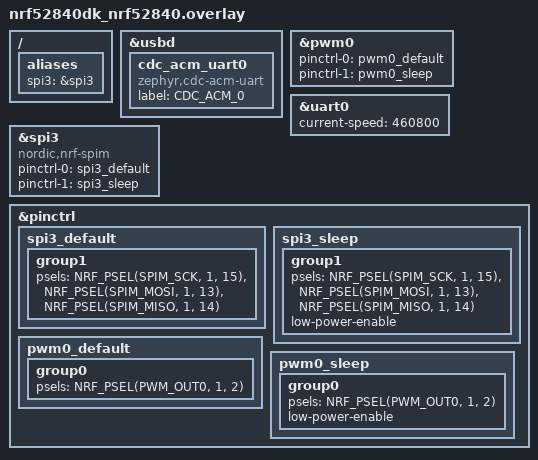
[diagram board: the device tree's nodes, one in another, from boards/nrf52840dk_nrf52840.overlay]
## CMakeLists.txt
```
cmake_minimum_required(VERSION 3.20.0)
find_package(Zephyr REQUIRED HINTS $ENV{ZEPHYR_BASE})

project(ADS1298_Test)
target_include_directories(app PRIVATE include)

target_sources(app PRIVATE
  src/main.c
  src/ads1298.c
  src/imu_task.c
  src/ble_link.c
  src/device_id.c
)
```

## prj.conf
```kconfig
#####################################
# prj.conf — EMG(ADS1298) + IMU TX
# nRF52840 DK, BLE NUS + USB CDC + RTT log
#####################################

# =============================================================
#                    ★  BLE / NUS  ★
# =============================================================
CONFIG_BT=y
CONFIG_BT_PERIPHERAL=y
CONFIG_BT_CENTRAL=n

# 安全 / 绑定（Just-Works + SMP，加密但不要求 PIN）
CONFIG_BT_SMP=y
CONFIG_BT_BONDABLE=y
CONFIG_BT_PRIVACY=y
CONFIG_SETTINGS=y
CONFIG_BT_SETTINGS=y

# NUS 服务：TX = Server
CONFIG_BT_NUS=y
CONFIG_BT_NUS_CLIENT=n

# 吞吐 & MTU & PHY（跟 Gesture_Recognition 一致）
CONFIG_BT_CTLR_PHY_2M=y
CONFIG_BT_CTLR_DATA_LENGTH_MAX=251
CONFIG_BT_L2CAP_TX_MTU=247
CONFIG_BT_BUF_ACL_TX_SIZE=251
CONFIG_BT_BUF_ACL_RX_SIZE=251
CONFIG_BT_BUF_ACL_TX_COUNT=12
CONFIG_BT_BUF_ACL_RX_COUNT=12
CONFIG_BT_L2CAP_TX_BUF_COUNT=12
CONFIG_BT_L2CAP_TX_FRAG_COUNT=3
CONFIG_BT_CONN_TX_MAX=20
CONFIG_BT_GATT_CLIENT=y
CONFIG_BT_GATT_DM=y
CONFIG_BT_BUF_CMD_TX_COUNT=4
CONFIG_BT_BUF_EVT_RX_SIZE=255
CONFIG_BT_BUF_EVT_RX_COUNT=16
CONFIG_BT_CTLR_TX_PWR_PLUS_8=y

# 建议连接参数（约 7.5–15 ms）
CONFIG_BT_PERIPHERAL_PREF_MIN_INT=6
CONFIG_BT_PERIPHERAL_PREF_MAX_INT=12
CONFIG_BT_PERIPHERAL_PREF_LATENCY=0
CONFIG_BT_PERIPHERAL_PREF_TIMEOUT=400

# 设备名在代码里动态设置（device_bt_name_get）
CONFIG_BT_DEVICE_NAME_DYNAMIC=y

# =============================================================
#                    ★  线程 / 内存  ★
# =============================================================
CONFIG_MAIN_STACK_SIZE=4096
CONFIG_SYSTEM_WORKQUEUE_STACK_SIZE=2048
CONFIG_ISR_STACK_SIZE=2048
CONFIG_HEAP_MEM_POOL_SIZE=32768

CONFIG_THREAD_NAME=y
CONFIG_INIT_STACKS=y
# CONFIG_STACK_SENTINEL=y

# =============================================================
#                    ★  日志 / Console / RTT  ★
# =============================================================
CONFIG_LOG=y
CONFIG_LOG_MODE_DEFERRED=y
CONFIG_LOG_DEFAULT_LEVEL=3

CONFIG_USE_SEGGER_RTT=y
CONFIG_LOG_BACKEND_RTT=y
CONFIG_LOG_BACKEND_UART=n

CONFIG_PRINTK=y
CONFIG_CONSOLE=y
CONFIG_UART_CONSOLE=n         # 不占用 UART0
CONFIG_RTT_CONSOLE=y          # 控制台走 RTT，不占 CDC

# =============================================================
#                    ★  USB CDC (ADS1298 数据)  ★
# =============================================================
CONFIG_USB_DEVICE_STACK=y
CONFIG_USB_CDC_ACM=y
CONFIG_USB_DEVICE_PRODUCT="ADS1298 CDC"
CONFIG_USB_DEVICE_MANUFACTURER="BioSpur"

CONFIG_SERIAL=y
CONFIG_UART_LINE_CTRL=y

# 不让 Console 占用 CDC（我们用 RTT Console）
# 上面已设 UART_CONSOLE=n，这里就不用再关 CONSOLE 了

# =============================================================
#                    ★  GPIO / SPI / PINCTRL / PWM  ★
# =============================================================
CONFIG_GPIO=y
CONFIG_GPIO_NRFX=y
CONFIG_PINCTRL=y

CONFIG_SPI=y

CONFIG_PWM=y
CONFIG_PWM_NRFX=y

# =============================================================
#                    ★  I²C (IMU: JY901B / WT901 等)  ★
# =============================================================
CONFIG_I2C=y
CONFIG_I2C_NRFX=y
CONFIG_I2C_INIT_PRIORITY=50

# =============================================================
#                    ★  UART (预留给 UWB / BMD101 等)  ★
# =============================================================
CONFIG_UART_NRFX=y
CONFIG_UART_ASYNC_API=y
CONFIG_UART_INTERRUPT_DRIVEN=y
CONFIG_RING_BUFFER=y

# =============================================================
#                    ★  ADC  ★
# =============================================================
# 不用 SAADC：EMG 走 ADS1298 SPI + BMD101 走 UART
CONFIG_ADC=n
CONFIG_ADC_NRFX_SAADC=n
CONFIG_ADC_ASYNC=n

# =============================================================
#                    ★  DK LED & Buttons  ★
# =============================================================
CONFIG_DK_LIBRARY=y

# =============================================================
#                    ★  libc / 浮点格式化  ★
# =============================================================
CONFIG_NEWLIB_LIBC=y
CONFIG_CBPRINTF_FP_SUPPORT=y

# =============================================================
#                    ★  同步 / 信号量上限  ★
# =============================================================
CONFIG_SEM_VALUE_MAX=32767

# =============================================================
#                    ★  电源管理  ★
# =============================================================
# 关闭自动省电，避免 SPI / USB 等被自动关掉
CONFIG_PM=n

# =============================================================
#                    ★  定时器 / 其它  ★
# =============================================================
CONFIG_NRFX_TIMER2=y
CONFIG_ASSERT=y
```

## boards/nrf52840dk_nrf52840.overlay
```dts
/ {
    aliases { spi3 = &spi3; };
};

/* 启用 USB 设备控制器 */
&usbd {
    status = "okay";

    /* 新建一个 CDC ACM 节点，label 一定要给，这个就是设备名 */
    cdc_acm_uart0: cdc_acm_uart0 {
        compatible = "zephyr,cdc-acm-uart";
        label = "CDC_ACM_0";
        status = "okay";
    };
};

/* ✅ 修正：pwm0 用 pinctrl 方式绑定到 P1.02（PWM0_CH0） */
&pwm0 {
    status = "okay";
    pinctrl-0 = <&pwm0_default>;
    pinctrl-1 = <&pwm0_sleep>;
    pinctrl-names = "default", "sleep";
};

/* UART0 是否开启随你，这里保留 */
&uart0 {
    current-speed = <460800>;
    status = "okay";
};

/* 你的 SPI3 + pinctrl（保持不变） */
&spi3 {
    compatible = "nordic,nrf-spim";
    status = "okay";
    pinctrl-0 = <&spi3_default>;
    pinctrl-1 = <&spi3_sleep>;
    pinctrl-names = "default", "sleep";
    /* 如需驱动自动控片选，取消下面注释，并在 C 里配置 spi_cfg.cs */
    // cs-gpios = <&gpio1 12 GPIO_ACTIVE_LOW>;
};

/* pinctrl 区域：保留你原来的 SPI3 分组，并新增 PWM0 分组 */
&pinctrl {
    /* ===== SPI3（保持不变） ===== */
    spi3_default: spi3_default {
        group1 {
            psels = <NRF_PSEL(SPIM_SCK,  1, 15)>,
                    <NRF_PSEL(SPIM_MOSI, 1, 13)>,
                    <NRF_PSEL(SPIM_MISO, 1, 14)>;
        };
    };
    spi3_sleep: spi3_sleep {
        group1 {
            psels = <NRF_PSEL(SPIM_SCK,  1, 15)>,
                    <NRF_PSEL(SPIM_MOSI, 1, 13)>,
                    <NRF_PSEL(SPIM_MISO, 1, 14)>;
            low-power-enable;
        };
    };

    /* ===== PWM0: 将 PWM0_CH0 绑定到 P1.02 ===== */
    pwm0_default: pwm0_default {
        group0 {
            psels = <NRF_PSEL(PWM_OUT0, 1, 2)>;   /* P1.02 */
        };
    };
    pwm0_sleep: pwm0_sleep {
        group0 {
            psels = <NRF_PSEL(PWM_OUT0, 1, 2)>;
            low-power-enable;
        };
    };
};
```

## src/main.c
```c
/* src/main.c */

#include <zephyr/kernel.h>
#include <zephyr/logging/log.h>
#include <zephyr/sys/byteorder.h>

#include "app_config.h"
#include "device_id.h"
#include "ble_link.h"
#include "ads1298.h"
#include "imu_task.h"

LOG_MODULE_REGISTER(main, LOG_LEVEL_INF);

/* ============ EMG -> BLE 'E' 帧打包 ============ */

/* EMG 帧序号（u16，溢出自然回绕） */
static uint16_t g_emg_seq = 0;

static uint16_t next_emg_seq(void)
{
    uint16_t v = g_emg_seq;
    g_emg_seq = (uint16_t)(v + 1);
    return v;
}

/* 缓存 EMG 样本：最多 EMG_SAMPLES_PER_FRAME 组，每组 8 通道 */
static int32_t emg_buf[EMG_SAMPLES_PER_FRAME][8];
static uint8_t emg_buf_count = 0;

/* 把 emg_buf 里当前攒的 sample_count 组打成一帧发出去 */
static void emg_flush_frame(uint8_t sample_count)
{
    if (sample_count == 0) {
        return;
    }

#if EN_BLE
    uint8_t  f[BLE_BUF_SIZE];
    uint16_t p = 0;

    /* 帧头：AA + 'E' */
    f[p++] = 0xAA;
    f[p++] = 'E';

    /* seq (u16 LE) */
    sys_put_le16(next_emg_seq(), &f[p]); p += 2;

    /* dev_id16（与 BT 名字一一对应） */
    sys_put_le16(device_id_get16(), &f[p]); p += 2;

    /* 全局时间戳：host_ms（按第 0 组 sample 的时间） */
    sys_put_le32(ble_link_now_host_ms(), &f[p]); p += 4;

    /* 采样率：与 ads1298.c 中 EMG_SAMPLE_RATE_SPS 一致 */
    sys_put_le16(EMG_SAMPLE_RATE_SPS, &f[p]); p += 2;

    /* 本帧包含的 sample 数（1~EMG_SAMPLES_PER_FRAME） */
    f[p++] = sample_count;

    /* 写入 sample_count 组，每组 8 通道 24bit (3B) */
    for (uint8_t s = 0; s < sample_count; s++) {
        for (int ch = 0; ch < 8; ch++) {
            int32_t v = emg_buf[s][ch];
            f[p++] = (uint8_t)((v >> 16) & 0xFF);
            f[p++] = (uint8_t)((v >>  8) & 0xFF);
            f[p++] = (uint8_t)( v        & 0xFF);
        }
    }

    (void)ble_link_send(f, p);
#else
    ARG_UNUSED(sample_count);
    /* 如果 EN_BLE=0，就什么都不发，只是丢掉缓存 */
#endif
}

/* ADS1298 每来一个时间点（8 路样本）就会回调一次 */
static void emg_frame_cb(const int32_t ch_code[8], const uint8_t status[3])
{
    ARG_UNUSED(status);

    /* 把当前这组 8 通道塞进缓存 */
    if (emg_buf_count < EMG_SAMPLES_PER_FRAME) {
        for (int i = 0; i < 8; i++) {
            emg_buf[emg_buf_count][i] = ch_code[i];
        }
        emg_buf_count++;
    }

    /* 攒满 EMG_SAMPLES_PER_FRAME 组，就打一帧发出去 */
    if (emg_buf_count >= EMG_SAMPLES_PER_FRAME) {
        emg_flush_frame(emg_buf_count);
        emg_buf_count = 0;
    }
}

/* ============ 主入口 ============ */

int main(void)
{
    int ret;
    int ble_ok = 0;

    /* 1) 设备 ID & BT 名字（这里会生成 ESxxxx/eFxxxx 名字） */
    device_id_init();
    LOG_INF("=== EMG + IMU TX Boot ===");
    LOG_INF("BT name: %s, dev_id: 0x%04x",
            device_bt_name_get(), device_id_get16());

#if EN_BLE
    /* 2) 初始化 BLE + NUS + APP_KEY/TSYNC 支持 */
    ret = ble_link_init();
    if (ret) {
        LOG_ERR("ble_link_init failed: %d", ret);
    } else {
        ble_ok = 1;
    }
#endif

#if EN_IMU
    /* 3) IMU：沿用 Gesture_Recognition 的逻辑（发 'I' 帧） */
    ret = imu_init();
    if (ret) {
        LOG_ERR("imu_init failed: %d", ret);
    } else {
        imu_start();
    }
#endif

#if EN_EMG
    /* 4) ADS1298：初始化 + 注册回调 + 启动采样线程 */
    ret = ads1298_init();
    if (ret) {
        LOG_ERR("ads1298_init failed: %d", ret);
    } else {
        /* 如果 BLE 成功初始化，就注册 EMG->BLE 回调；否则只跑 USB 输出 */
        if (ble_ok) {
            ads1298_set_frame_callback(emg_frame_cb);
        } else {
            ads1298_set_frame_callback(NULL);
        }

        /* 启动采样（内部仍然通过 USB CDC 输出 31B 帧，不影响） */
        ads1298_start();
    }
#endif

    /* 5) main 线程什么都不干，直接睡死 */
    while (1) {
        k_sleep(K_FOREVER);
    }

    return 0;
}
```

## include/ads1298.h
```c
/* src/ads1298.h */

#pragma once

#include <stdint.h>

/* 初始化 ADS1298 + SPI + GPIO + USB CDC + DRDY 监视线程
 *
 * 返回 0 表示成功，负值表示错误。
 */
int ads1298_init(void);

/* 启动 ADS1298 采样线程：
 *  - 内部会进入 while(1) 循环：
 *      * 等 DRDY
 *      * SPI 读出 8 路 24bit 数据
 *      * 组装 0xAA 帧（31B）
 *      * 通过 USB CDC 发出去
 *      * RTT 每 N 帧打印一次调试信息
 */
void ads1298_start(void);

/* 可选：注册一个“每帧 EMG 数据”的回调。
 *
 * 这个回调在采样线程里被调用：
 *   callback(ch_code[8], status[3]);
 *
 * 你以后要加：
 *   - BLE NUS 发送 EMG
 *   - 或者本地做特征提取
 * 就可以在外面实现一个函数，然后通过这里注册进去。
 */
typedef void (*ads1298_frame_cb_t)(const int32_t ch_code[8],
                                   const uint8_t status[3]);

void ads1298_set_frame_callback(ads1298_frame_cb_t cb);
```

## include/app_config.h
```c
/* src/app_config.h
 *
 * Common includes + global config for ESxxxx TX (IMU + EMG).
 */

#pragma once

#include <zephyr/kernel.h>
#include <zephyr/device.h>
#include <zephyr/devicetree.h>
#include <zephyr/drivers/gpio.h>
#include <zephyr/drivers/i2c.h>
#include <zephyr/drivers/uart.h>
#include <zephyr/sys/printk.h>
#include <zephyr/sys/byteorder.h>
#include <zephyr/sys/util.h>
#include <zephyr/sys/atomic.h>
#include <zephyr/sys/sys_io.h>
#include <zephyr/settings/settings.h>
#include <string.h>
#include <zephyr/bluetooth/bluetooth.h>
#include <zephyr/bluetooth/conn.h>
#include <zephyr/bluetooth/gatt.h>
#include <bluetooth/services/nus.h>
#include <dk_buttons_and_leds.h>
#include <math.h>

/* ========================= Global toggles ========================= */
#define DEBUG_LOG_ENABLE   1
#if DEBUG_LOG_ENABLE
  #define LOGF(...)  printk(__VA_ARGS__)
#else
  #define LOGF(...)  do {} while (0)
#endif

#define EN_BLE 1
#define EN_IMU 1 
#define EN_EMG 1
#define EN_UWB 0 // Temporarily disable UWB will be added later on next HW revision

/* ========================= RT settings ========================= */
#define BLE_PRIO   3 //BLE prio higher than IMU and EMG to ensure data flow
#define IMU_PRIO   5 
#define EMG_PRIO   4 // EMG prio higher than IMU to reduce latency
#define UWB_PRIO   4 // dont care for now



#define BLE_STACK_SIZE  1280
#define IMU_STACK_SIZE  1536
#define UWB_STACK_SIZE  1536
#define EMG_STACK_SIZE  2048
#define BLE_BUF_SIZE    256

/* EMG: 每个 BLE 帧里包含多少个时间点的 8 路样本
 * 可选：1 / 2 / 3 / 4
 */
#define EMG_SAMPLES_PER_FRAME   4 //compress to 4 samples per frame to reduce BLE packet rate
#define EMG_SAMPLE_RATE_SPS     500

#if (EMG_SAMPLE_RATE_SPS != 250)  && \
    (EMG_SAMPLE_RATE_SPS != 500)  && \
    (EMG_SAMPLE_RATE_SPS != 1000) && \
    (EMG_SAMPLE_RATE_SPS != 2000) && \
    (EMG_SAMPLE_RATE_SPS != 4000)
#error "EMG_SAMPLE_RATE_SPS must be one of: 250/500/1000/2000/4000"
#endif

#if (EMG_SAMPLES_PER_FRAME < 1) || (EMG_SAMPLES_PER_FRAME > 4)
#error "EMG_SAMPLES_PER_FRAME must be 1..4"
#endif

static inline uint32_t ts_ms(void)
{
    return (uint32_t)k_uptime_get_32();
}
```

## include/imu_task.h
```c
/* src/imu_task.h */

#pragma once

int  imu_init(void);   /* 做一次 POST 等 */
void imu_start(void);  /* 让线程开始跑采样 */
void imu_set_rate_phase(uint16_t target_fps, uint16_t phase_ms);
```

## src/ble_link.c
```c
/* src/ble_link.c — TX（Peripheral, A 组 APP_KEY=936656）
 *
 * - 不再使用蓝牙层 PIN / Passkey（Just-Works SMP 或无加密）
 * - 连接成功后周期性发送 APP_KEY 帧：'K' + 4 字节 936656（LE）
 * - NUS Server，主动发送 IMU/UWB 数据
 * - 支持 RX 发送的 TSYNC / RSLOT 指令
 * - 使用静态内存池 (k_mem_slab) 管理 BLE 发送 FIFO，避免 k_malloc 失败
 */

#include "app_config.h"
#include "device_id.h"
#include "ble_link.h"

#include <zephyr/bluetooth/bluetooth.h>
#include <zephyr/bluetooth/conn.h>
#include <zephyr/bluetooth/gatt.h>
#include <zephyr/bluetooth/hci.h>
#include <zephyr/settings/settings.h>
#include <zephyr/kernel.h>
#include <zephyr/device.h>

#include <bluetooth/services/nus.h>

#include <dk_buttons_and_leds.h>
#include <string.h>
#include <stdint.h>
#include <zephyr/sys/printk.h>

/* TSYNC: host_time_offset_ms = host_ms - uptime_ms */
static int64_t g_host_time_offset_ms = 0;

/* ===================================================== */
/* 可选：imu 控制入口的弱符号 stub
 *  - 如果工程里已经有真正的 imu_handle_ctrl_from_ble()，会覆盖掉这个 weak 版本
 *  - 如果没有，实现就什么都不做，但保证链接通过，也不用去改 imu_task.c
 * ===================================================== */
__attribute__((weak)) void imu_handle_ctrl_from_ble(const uint8_t *data, uint16_t len)
{
    ARG_UNUSED(data);
    ARG_UNUSED(len);
}

/* ====================== APP_KEY (A 组) ====================== */

#define APP_KEY_VALUE     936656U    /* APP 级别分组密钥（A 组） */
#define APP_KEY_INTERVAL  2000       /* 周期发送 APP_KEY 的间隔(ms) */

/* ====================== NUS FIFO & 发送 ====================== */

/* 发送 FIFO：外部通过 ble_link_send() 塞包进来，内部 TX 线程统一 bt_nus_send() */

K_FIFO_DEFINE(ble_tx_fifo);

struct ble_tx_item {
    void    *fifo_reserved;
    uint16_t len;
    uint8_t  data[BLE_BUF_SIZE];
};

/* 静态内存池：最多同时挂在 FIFO 里的包数量（根据你 IMU 频率略微留富余） */
#define BLE_TX_POOL_ITEMS 64

K_MEM_SLAB_DEFINE(ble_tx_slab,
                  sizeof(struct ble_tx_item),
                  BLE_TX_POOL_ITEMS,
                  4);

static struct bt_conn *current_conn;
static uint32_t g_ble_drop_count = 0;

/* BLE 就绪信号：init 完成后才允许发包 */
static struct k_sem ble_ready;

/* ====================== APP_KEY 周期发送逻辑 ====================== */

static struct k_work_delayable app_key_work;

/* 实际打包并发送 'K' + APP_KEY_VALUE 的函数 */
static void send_app_key_once(void)
{
    uint8_t buf[1 + 4];

    buf[0] = 'K';
    sys_put_le32(APP_KEY_VALUE, &buf[1]);

    if (!ble_link_send(buf, sizeof(buf))) {
        printk("[TX] APP_KEY enqueue failed\n");
    } else {
        /* 正常情况这里就安静地跑，不刷屏 */
        /* printk("[TX] APP_KEY queued (%u)\n", APP_KEY_VALUE); */
    }
}

/* 延时任务：每隔 APP_KEY_INTERVAL 通过 FIFO 发一次 APP_KEY 帧 */
static void app_key_work_handler(struct k_work *work)
{
    ARG_UNUSED(work);

    /* 没连上就不发，也不 reschedule，等下次 connected 再 schedule */
    if (!EN_BLE || !current_conn) {
        return;
    }

    send_app_key_once();
    k_work_schedule(&app_key_work, K_MSEC(APP_KEY_INTERVAL));
}

/* ====================== NUS FIFO 对外发送接口 ====================== */

bool ble_link_send(const uint8_t *data, uint16_t len)
{
    if (!EN_BLE) {
        return false;
    }

    if (!data) {
        g_ble_drop_count++;
        return false;
    }

    if (!current_conn) {
        g_ble_drop_count++;
        return false;
    }

    if (len == 0 || len > BLE_BUF_SIZE) {
        g_ble_drop_count++;
        return false;
    }

    void *block = NULL;
    int slab_err = k_mem_slab_alloc(&ble_tx_slab, &block, K_NO_WAIT);
    if (slab_err) {
        /* 内存池满了，丢包 */
        g_ble_drop_count++;
        return false;
    }

    struct ble_tx_item *item = (struct ble_tx_item *)block;
    item->len = len;
    memcpy(item->data, data, len);

    k_fifo_put(&ble_tx_fifo, item);
    return true;
}

/* ====================== NUS 发送后台线程 ====================== */

static K_THREAD_STACK_DEFINE(ble_thread_stack, BLE_STACK_SIZE);
static struct k_thread ble_thread_data;

static void ble_tx_thread(void *p1, void *p2, void *p3)
{
    ARG_UNUSED(p1);
    ARG_UNUSED(p2);
    ARG_UNUSED(p3);

    /* 等 BLE ready */
    k_sem_take(&ble_ready, K_FOREVER);

    while (1) {
        struct ble_tx_item *item =
            (struct ble_tx_item *)k_fifo_get(&ble_tx_fifo, K_FOREVER);

        if (item && current_conn) {
            int err = bt_nus_send(current_conn, item->data, item->len);
            if (err) {
                printk("[TX] bt_nus_send err=%d len=%u\n",
                       err, item->len);
            }
        } else {
            /* 未连接或空项，统计丢包 */
            if (item) {
                g_ble_drop_count++;
            }
        }

        if (item) {
            k_mem_slab_free(&ble_tx_slab, (void *)item);
        }
    }
}

/* ====================== 连接回调 & 广播 ====================== */

static void exchange_mtu_cb(struct bt_conn *conn, uint8_t err,
                            struct bt_gatt_exchange_params *params)
{
    ARG_UNUSED(conn);
    ARG_UNUSED(params);

    if (err) {
        printk("[TX] MTU exchange failed (err 0x%02x)\n", err);
    } else {
        printk("[TX] MTU exchange successful\n");
    }
}

static struct bt_gatt_exchange_params exch_mtu_params;

static void connected_cb(struct bt_conn *conn, uint8_t err)
{
    if (err) {
        printk("[TX] Connection failed (err 0x%02x)\n", err);
        return;
    }

    current_conn = bt_conn_ref(conn);
    dk_set_led_on(DK_LED2);

    exch_mtu_params.func = exchange_mtu_cb;
    bt_gatt_exchange_mtu(conn, &exch_mtu_params);

    /* Prefer low-latency params for 1 kSPS streaming */
    const struct bt_le_conn_param *param = BT_LE_CONN_PARAM(6, 12, 0, 400);
    bt_conn_le_param_update(conn, param);

    printk("[TX] Connected\n");

    /* 连接建立后启动 APP_KEY 周期发送 */
    k_work_schedule(&app_key_work, K_MSEC(APP_KEY_INTERVAL));
}

static void disconnected_cb(struct bt_conn *conn, uint8_t reason)
{
    printk("[TX] Disconnected (reason 0x%02x)\n", reason);

    if (current_conn) {
        bt_conn_unref(current_conn);
        current_conn = NULL;
    }

    dk_set_led_off(DK_LED2);

    /* 断线后重新开始广播 */
    const char *bt_name = device_bt_name_get();

    /* 沿用你原来的广播配置，只是重新启动 */
    const struct bt_data ad[] = {
        BT_DATA_BYTES(BT_DATA_FLAGS, (BT_LE_AD_GENERAL | BT_LE_AD_NO_BREDR)),
        BT_DATA(BT_DATA_NAME_COMPLETE, bt_name, strlen(bt_name)),
    };
    const struct bt_data sd[] = {
        BT_DATA_BYTES(BT_DATA_UUID128_ALL, BT_UUID_NUS_VAL),
    };
    int err = bt_le_adv_start(BT_LE_ADV_CONN, ad, ARRAY_SIZE(ad),
                              sd, ARRAY_SIZE(sd));
    printk("[TX] Restart adv after disconnect: %d\n", err);
}

static struct bt_conn_cb conn_cb = {
    .connected    = connected_cb,
    .disconnected = disconnected_cb,
};

/* ======================= NUS RX（来自 RX） ======================= */

static void nus_recv_cb(struct bt_conn *conn,
                        const uint8_t *data, uint16_t len)
{
    ARG_UNUSED(conn);

    if (len == 0) {
        return;
    }

    /* 优先解析 TSYNC：AA 'T' + host_ms(u64, LE) */
    if (len == 10 && data[0] == 0xAA && data[1] == 'T') {
        uint64_t host_ms = 0;
        memcpy(&host_ms, &data[2], 8);

        uint64_t up = (uint64_t)k_uptime_get();
        g_host_time_offset_ms = (int64_t)host_ms - (int64_t)up;

        printk("[TX] TSYNC: host_ms=%llu up=%llu offset=%lld\n",
               (unsigned long long)host_ms,
               (unsigned long long)up,
               (long long)g_host_time_offset_ms);
        return;
    }

    /* 其他控制命令（例如以后扩展的 RSLOT 'R'），仍然透传给 IMU 层 */
    imu_handle_ctrl_from_ble(data, len);
}

static struct bt_nus_cb nus_cb = {
    .received = nus_recv_cb,
};

/* ====================== NUS TX 线程入口 ====================== */

static void ble_thread_start(void)
{
    k_thread_create(&ble_thread_data, ble_thread_stack,
                    K_THREAD_STACK_SIZEOF(ble_thread_stack),
                    ble_tx_thread,
                    NULL, NULL, NULL,
                    BLE_PRIO, 0, K_NO_WAIT);
}

/* ====================== 对外辅助接口实现 ====================== */

/* main.c 使用：BLE 发送丢包数 */
uint32_t ble_link_get_drop_count(void)
{
    return g_ble_drop_count;
}

/* imu_task.c / uwb_task.c 使用：返回 host 时间戳 ms
 * 头文件 ble_link.h 里是 uint32_t，这里保持一致
 */
uint32_t ble_link_now_host_ms(void)
{
    uint64_t up = (uint64_t)k_uptime_get();
    int64_t host_ms_64 = (int64_t)up + g_host_time_offset_ms;

    if (host_ms_64 < 0) {
        host_ms_64 = 0;
    }
    return (uint32_t)host_ms_64;
}

/* ====================== 对外初始化接口 ====================== */

int ble_link_init(void)
{
    if (!EN_BLE) {
        k_sem_init(&ble_ready, 0, 1);
        k_sem_give(&ble_ready);
        ble_thread_start();
        return 0;
    }

    int err = bt_enable(NULL);
    if (err) {
        printk("[TX] bt_enable error %d\n", err);
        return err;
    }

    /* 允许从 Flash 里加载历史 bonding / 配置（本次会被下面的 bt_unpair 清空） */
    settings_load();
    int unpair_err = bt_unpair(BT_ID_DEFAULT, NULL);
    printk("[TX] bt_unpair(all) -> %d\n", unpair_err);

    /* 注册连接回调（连上/断线 + 自动重启广播） */
    bt_conn_cb_register(&conn_cb);

    /* 初始化 NUS Service */
    err = bt_nus_init(&nus_cb);
    if (err) {
        printk("[TX] bt_nus_init %d\n", err);
        return err;
    }

    /* 设置广播名：eFxxxx（来自 device_id.c 的 device_bt_name_get） */
    const char *bt_name = device_bt_name_get();
    bt_set_name(bt_name);

    const struct bt_data ad[] = {
        BT_DATA_BYTES(BT_DATA_FLAGS, (BT_LE_AD_GENERAL | BT_LE_AD_NO_BREDR)),
        BT_DATA(BT_DATA_NAME_COMPLETE, bt_name, strlen(bt_name)),
    };
    const struct bt_data sd[] = {
        BT_DATA_BYTES(BT_DATA_UUID128_ALL, BT_UUID_NUS_VAL),
    };

    err = bt_le_adv_start(BT_LE_ADV_CONN, ad, ARRAY_SIZE(ad),
                          sd, ARRAY_SIZE(sd));
    printk("[TX] ADV start ret=%d name=%s\n", err, bt_name);

    dk_leds_init();
    dk_set_led_on(DK_LED1);  /* 上电指示 */

    /* 初始化 APP_KEY 周期任务 */
    k_work_init_delayable(&app_key_work, app_key_work_handler);

    /* 通知 TX 线程可以开始工作（允许发包） */
    k_sem_init(&ble_ready, 0, 1);
    k_sem_give(&ble_ready);

    ble_thread_start();

    return 0;
}
```

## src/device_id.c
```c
/* src/device_id.c */

#include "app_config.h"
#include "device_id.h"

/* Device name / ID state (was static in main.c) */
static char     bt_name[8];
static uint16_t dev_id16 = 0;

void device_id_init(void)
{
    uint32_t id0 = sys_read32(0x10000060);
    uint8_t b0 = (id0 >> 0) & 0xFF;
    uint8_t b1 = (id0 >> 8) & 0xFF;
    dev_id16 = ((uint16_t)b1 << 8) | b0;
    snprintk(bt_name, sizeof(bt_name), "ES%02X%02X", b0, b1);
}

uint16_t device_id_get16(void)
{
    return dev_id16;
}

const char *device_bt_name_get(void)
{
    return bt_name;
}
```

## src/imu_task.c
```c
/* src/imu_task.c — WT901 / JY61P / WT61P IMU over I2C
 *
 * 目标：
 *  - IMU 内部 200 Hz 输出（RRATE=0x0B，可在 imu_config_200hz 里改）
 *  - 采样线程：固定 IMU_ODR_HZ（默认 120Hz，可设 200Hz）轮询 I2C，只采样不发 BLE
 *  - 发送线程：从 FIFO 聚合 1~4 个 sample，按配置 fps（默认 200Hz，
 *    多 TX 情况下一般设置为 50Hz）发送 'I' 帧
 *  - R 命令：设置 “发送 fps (target_fps)” 和 “相位偏移 phase_ms”（多 TX 分时隙）
 *  - 帧格式 'I'：
 *        0  : 0xAA
 *        1  : 'I'
 *        2-3: seq (u16, LE)
 *        4-5: dev_id (u16, LE)
 *        6-9: t_ms (u32, LE, ble_link_now_host_ms)
 *        10-11: fps (u16, LE)  —— 实际当前发送 fps
 *        12: sample_count (u8)
 *        后面: sample_count × 20B，每个 sample =
 *              10×int16(ax,ay,az,gx,gy,gz,q0,q1,q2,q3)
 */

#include "app_config.h"
#include "device_id.h"
#include "ble_link.h"
#include "imu_task.h"

#include <string.h>
#include <errno.h>
#include <stdint.h>
#include <stdbool.h>

#include <zephyr/device.h>
#include <zephyr/drivers/i2c.h>
#include <zephyr/kernel.h>
#include <zephyr/sys/byteorder.h>

/* ========================= IMU 硬件配置 ========================= */

/* WT61P / WT901 I2C 地址与寄存器 */
#define IMU_I2C_ADDR            0x50        /* WT61P / JY901 / JY61P 7-bit I2C 地址 */

/* 原始传感器数据寄存器：AX ~ AZ + GX ~ GZ (+ Hx~Hz)，从 0x34 开始 */
#define IMU_REG_START           0x34        /* AX 寄存器起始地址 */
#define IMU_REG_LEN             18          /* AX~AZ + GX~GZ + HX~HZ 共 18 字节 */
#define IMU_RAW_USED_LEN        12          /* 只用前 12 字节：AX~AZ + GX~GZ */

/* 四元数寄存器：基于 WitMotion 标准协议
 * WT 系列通常为：
 *   0x51/0x52: q0 (L/H)
 *   0x53/0x54: q1 (L/H)
 *   0x55/0x56: q2 (L/H)
 *   0x57/0x58: q3 (L/H)
 * 如你的固件不同，直接改下面两个宏即可。
 */
#define IMU_REG_QUAT_START      0x51
#define IMU_REG_QUAT_LEN        8           /* q0~q3 共 8 字节 */

/* IMU 内部输出速率（ODR）：这里用 120Hz，你可以改成 200 试试
 * 同时记得把 RRATE 对应改为 0x0B（200Hz）或合适值。
 */
#define IMU_ODR_HZ              100         /* Kann bis zu 200Hz */
#define IMU_SAMPLE_PERIOD_MS    (1000 / IMU_ODR_HZ)

/* 每帧最多聚合的 sample 数量：1~4（200Hz / 50Hz = 4） */
#define IMU_SAMPLES_PER_FRAME_MAX   4

/* 手动控制每帧聚合的 sample 数量：
 *  1 = 每包 1 个 sample（原来的行为）
 *  2 = 每包 2 个 sample
 *  3/4 = 每包 3/4 个 sample（上限不超过 IMU_SAMPLES_PER_FRAME_MAX）
 *
 * 后面你可以直接改这个宏的值做实验。
 */
#ifndef IMU_DATA_PER_PACK
#define IMU_DATA_PER_PACK  2
#endif

/* R 命令配置的“发送 fps”，默认 200（单 TX 场景） */
#define IMU_FPS_DEFAULT         200

/* FIFO 大小：纯原始 sample 数量（越大越抗抖，但占 RAM） */
#define IMU_FIFO_SIZE           256

/* I2C 设备：默认 i2c0，如果 overlay 里 IMU 接在别的 bus，请改 node label */
static const struct device *const imu_i2c = DEVICE_DT_GET(DT_NODELABEL(i2c0));

/* ========================= 基本数据结构 ========================= */

struct imu_sample_raw {
    int16_t ax;
    int16_t ay;
    int16_t az;
    int16_t gx;
    int16_t gy;
    int16_t gz;
    int16_t q0;
    int16_t q1;
    int16_t q2;
    int16_t q3;
};

static inline int16_t le16(const uint8_t *p)
{
    /* 文档约定：DATA = (H << 8) | L，小端 */
    return (int16_t)((((int16_t)p[1]) << 8) | p[0]);
}

/* ========================= FIFO / 状态变量 ========================= */

/* 采样启动信号：main.c 调 imu_start() 之后采样线程才开始跑 */
static struct k_sem   imu_start_sem;

/* FIFO：采样线程 -> 发送线程 */
static struct imu_sample_raw imu_fifo[IMU_FIFO_SIZE];
static uint16_t fifo_head;   /* 写指针 */
static uint16_t fifo_tail;   /* 读指针 */
static struct k_mutex fifo_lock;

/* R 命令配置的“发送 fps” + “相位偏移” */
static volatile uint16_t g_target_fps  = IMU_FPS_DEFAULT; /* 实际发包 fps 目标（如 50/100/200） */
static volatile uint16_t g_phase_ms    = 0;               /* 多 TX 分时隙用 */

/* IMU 'I' 帧的 seq 计数器 */
static uint16_t seq_imu;
static struct imu_sample_raw last_sample;
static bool last_sample_valid;

/* ========================= FIFO 辅助函数 ========================= */

static inline bool fifo_empty(void)
{
    return fifo_head == fifo_tail;
}

static inline bool fifo_full(void)
{
    return (uint16_t)((fifo_head + 1U) % IMU_FIFO_SIZE) == fifo_tail;
}

/* 向 FIFO 推入一个 sample：满则覆盖最旧的（tail 往前挪） */
static void fifo_push(const struct imu_sample_raw *s)
{
    k_mutex_lock(&fifo_lock, K_FOREVER);

    if (fifo_full()) {
        /* 覆盖最旧的：tail 前进一格 */
        fifo_tail = (uint16_t)((fifo_tail + 1U) % IMU_FIFO_SIZE);
    }

    imu_fifo[fifo_head] = *s;
    fifo_head = (uint16_t)((fifo_head + 1U) % IMU_FIFO_SIZE);

    k_mutex_unlock(&fifo_lock);
}

/* 从 FIFO 弹出一个 sample：返回 true 表示成功 */
static bool fifo_pop(struct imu_sample_raw *out)
{
    bool ok = false;

    k_mutex_lock(&fifo_lock, K_FOREVER);

    if (!fifo_empty()) {
        *out = imu_fifo[fifo_tail];
        fifo_tail = (uint16_t)((fifo_tail + 1U) % IMU_FIFO_SIZE);
        ok = true;
    }

    k_mutex_unlock(&fifo_lock);
    return ok;
}

/* ========================= I2C 配置 & 读写 ========================= */

/* 配置 WT901 / JY61P / WT61P 输出速率为 200 Hz（RRATE=0x0B） */
static int imu_config_200hz(void)
{
    /* 这两条命令与你之前的保持一致，只是第二条改为 0x0B（200Hz） */
    uint8_t cmd1[3] = {0x69, 0x88, 0xB5};  /* 解锁/进入配置 */
    uint8_t cmd2[3] = {0x03, 0x09, 0x00};  /* RRATE = 0x0B -> 200 Hz RRATE = 0x09 -> 100 Hz*/

    int ret;

    ret = i2c_write(imu_i2c, cmd1, sizeof(cmd1), IMU_I2C_ADDR);
    if (ret) {
        LOGF("IMU cfg cmd1 failed: %d\n", ret);
        return ret;
    }
    k_msleep(2);

    ret = i2c_write(imu_i2c, cmd2, sizeof(cmd2), IMU_I2C_ADDR);
    if (ret) {
        LOGF("IMU cfg cmd2 failed: %d\n", ret);
        return ret;
    }
    k_msleep(5);

    LOGF("IMU configured to 200Hz (RRATE=0x0B)\n");
    return 0;
}

/* 连续读取 IMU 寄存器块 */
static int imu_i2c_read_block(uint8_t reg_start, uint8_t *buf, size_t len)
{
    int ret = i2c_write_read(imu_i2c,
                             IMU_I2C_ADDR,
                             &reg_start, 1,
                             buf, len);
    if (ret) {
        LOGF("IMU i2c_write_read failed: reg=0x%02X len=%u err=%d\n",
             reg_start, (unsigned int)len, ret);
    }
    return ret;
}

/* 读一帧原始 6 轴 + 四元数数据（不做去重）
 *
 * ACC/GYRO: 从 0x34 连续读 18 字节，取前 12 字节
 * QUAT    : 从 0x51 连续读 8 字节
 */
static int imu_read_one_sample(struct imu_sample_raw *out)
{
    uint8_t buf[IMU_REG_LEN];
    int ret = imu_i2c_read_block(IMU_REG_START, buf, sizeof(buf));
    if (ret) {
        return ret;
    }

    /* AX/AY/AZ = 0x34~0x36, GX/GY/GZ = 0x37~0x39，小端 */
    out->ax = le16(&buf[0]);
    out->ay = le16(&buf[2]);
    out->az = le16(&buf[4]);
    out->gx = le16(&buf[6]);
    out->gy = le16(&buf[8]);
    out->gz = le16(&buf[10]);

    /* 读取四元数 q0~q3 */
    uint8_t qbuf[IMU_REG_QUAT_LEN];
    ret = imu_i2c_read_block(IMU_REG_QUAT_START, qbuf, sizeof(qbuf));
    if (ret) {
        return ret;
    }

    out->q0 = le16(&qbuf[0]);
    out->q1 = le16(&qbuf[2]);
    out->q2 = le16(&qbuf[4]);
    out->q3 = le16(&qbuf[6]);

    return 0;
}

/* ========================= 'I' 帧打包 ========================= */

static inline uint16_t next_seq_imu(void)
{
    uint16_t v = seq_imu;
    seq_imu = (uint16_t)(v + 1);
    return v;
}

/* 发送一帧 'I' 包：samples[0..num_samples-1] */
static void imu_send_frame(uint32_t t_global_ms,
                           uint16_t fps,
                           const struct imu_sample_raw *samples,
                           uint8_t num_samples)
{
    if (!EN_IMU || !EN_BLE) return;
    if (num_samples == 0 || num_samples > IMU_SAMPLES_PER_FRAME_MAX) return;

    uint8_t  f[BLE_BUF_SIZE];
    uint16_t p = 0;

    /* 头部：AA 'I' */
    f[p++] = 0xAA;
    f[p++] = 'I';

    /* seq (u16, LE) */
    sys_put_le16(next_seq_imu(),      &f[p]); p += 2;

    /* device_id (u16, LE) */
    sys_put_le16(device_id_get16(),   &f[p]); p += 2;

    /* 时间戳：全局 host_ms */
    sys_put_le32(t_global_ms,         &f[p]); p += 4;

    /* 当前 fps（u16, LE）：实际本帧使用的 fps */
    sys_put_le16(fps,                 &f[p]); p += 2;

    /* sample_count (u8) */
    f[p++] = num_samples;

    /* samples: 每个 sample = 10×int16 小端 (ACC+GYRO+QUAT) */
    for (uint8_t i = 0; i < num_samples; i++) {
        const struct imu_sample_raw *s = &samples[i];

        sys_put_le16((uint16_t)s->ax,  &f[p]); p += 2;
        sys_put_le16((uint16_t)s->ay,  &f[p]); p += 2;
        sys_put_le16((uint16_t)s->az,  &f[p]); p += 2;
        sys_put_le16((uint16_t)s->gx,  &f[p]); p += 2;
        sys_put_le16((uint16_t)s->gy,  &f[p]); p += 2;
        sys_put_le16((uint16_t)s->gz,  &f[p]); p += 2;

        sys_put_le16((uint16_t)s->q0,  &f[p]); p += 2;
        sys_put_le16((uint16_t)s->q1,  &f[p]); p += 2;
        sys_put_le16((uint16_t)s->q2,  &f[p]); p += 2;
        sys_put_le16((uint16_t)s->q3,  &f[p]); p += 2;
    }

    (void)ble_link_send(f, p);
}

/* ========================= 采样线程：固定 IMU_ODR_HZ ========================= */

static void imu_sampling_thread(void *a, void *b, void *c)
{
    ARG_UNUSED(a);
    ARG_UNUSED(b);
    ARG_UNUSED(c);

    if (!EN_IMU) {
        return;
    }

    if (!device_is_ready(imu_i2c)) {
        LOGF("IMU I2C device not ready, sampling thread exit\n");
        return;
    }

    /* 等 main.c 中 imu_start() 放行 */
    k_sem_take(&imu_start_sem, K_FOREVER);
    LOGF("IMU sampling thread started\n");

    struct imu_sample_raw s;

    while (1) {
        uint32_t t0 = ts_ms();

        if (imu_read_one_sample(&s) == 0) {
            /* 推入 FIFO（满则覆盖最旧） */
            fifo_push(&s);
        }

        uint32_t t1    = ts_ms();
        uint32_t spent = t1 - t0;

        if (spent < IMU_SAMPLE_PERIOD_MS) {
            k_sleep(K_MSEC(IMU_SAMPLE_PERIOD_MS - spent));
        } else {
            k_yield();
        }
    }
}

static void imu_sending_thread(void *a, void *b, void *c)
{
    ARG_UNUSED(a);
    ARG_UNUSED(b);
    ARG_UNUSED(c);

    if (!EN_IMU) {
        return;
    }

    if (!device_is_ready(imu_i2c)) {
        LOGF("IMU I2C device not ready, sending thread exit\n");
        return;
    }

    LOGF("IMU sending thread started\n");

    uint32_t last_local  = k_uptime_get_32();
    uint32_t last_log_ms = ble_link_now_host_ms();
    uint32_t phase_acc   = 0;

    /* 我们现在用一个小数组，最多装 IMU_SAMPLES_PER_FRAME_MAX 个 sample */
    struct imu_sample_raw samples[IMU_SAMPLES_PER_FRAME_MAX];

    while (1) {
        if (!EN_BLE) {
            k_sleep(K_MSEC(10));
            last_local   = k_uptime_get_32();
            phase_acc    = 0;
            last_log_ms  = ble_link_now_host_ms();
            continue;
        }

        /* 当前目标 fps：由 R 命令配置；范围 clamp 到 1..IMU_ODR_HZ */
        uint16_t fps = g_target_fps;
        if (fps == 0) {
            fps = IMU_FPS_DEFAULT;
        }
        if (fps > IMU_ODR_HZ) {
            fps = IMU_ODR_HZ;
        }
        if (fps < 1) {
            fps = 1;
        }

        /* 1) 用本地时间算 dt_ms */
        uint32_t now_local = k_uptime_get_32();
        int32_t  diff      = (int32_t)(now_local - last_local);
        last_local         = now_local;

        uint32_t dt_ms = 0;

        if (diff <= 0 || diff > 1000) {
            phase_acc = 0;
            dt_ms     = 0;
        } else {
            dt_ms = (uint32_t)diff;
        }

        if (dt_ms > 0) {
            phase_acc += (uint32_t)fps * dt_ms;
        }

        /* 2) host 对齐后的时间戳（帧头用这个） */
        uint32_t now_host = ble_link_now_host_ms();

        /* 可能一次跨过多“包边界”，用 while 补齐 */
        while (phase_acc >= 1000U) {
            phase_acc -= 1000U;

            /* 本次希望聚合的 sample 数量（由宏控制），并夹在 1..MAX 之间 */
            uint8_t want = IMU_DATA_PER_PACK;
            if (want < 1) {
                want = 1;
            } else if (want > IMU_SAMPLES_PER_FRAME_MAX) {
                want = IMU_SAMPLES_PER_FRAME_MAX;
            }

            uint8_t got = 0;
            while (got < want) {
                if (!fifo_pop(&samples[got])) {
                    break;
                }
                got++;
            }

            if (got > 0) {
                /* sample_count = got */
                imu_send_frame(now_host, fps, samples, got);
                last_sample = samples[got - 1];
                last_sample_valid = true;
            } else {
                /* 没数据就退出这轮，避免空转 */
                break;
            }
        }

        /* 每秒打印一次调试信息（原来那段可以保留/删除） */
        if ((now_host - last_log_ms) >= 1000U) {
            last_log_ms = now_host;
            if (last_sample_valid) {
                LOGF("IMU send: fps=%u, phase_acc=%u, "
                     "ax=%d ay=%d az=%d gx=%d gy=%d gz=%d\n",
                     (unsigned int)fps, (unsigned int)phase_acc,
                     last_sample.ax, last_sample.ay, last_sample.az,
                     last_sample.gx, last_sample.gy, last_sample.gz);
            } else {
                LOGF("IMU send: fps=%u, phase_acc=%u\n",
                     (unsigned int)fps, (unsigned int)phase_acc);
            }
        }

        /* 发包线程不需要太细，1ms 轮询足够 */
        k_sleep(K_MSEC(1));
    }
}

/* ========================= 线程创建 ========================= */

K_THREAD_DEFINE(imu_sample_tid, IMU_STACK_SIZE, imu_sampling_thread,
                NULL, NULL, NULL, IMU_PRIO, 0, 0);

K_THREAD_DEFINE(imu_send_tid, IMU_STACK_SIZE, imu_sending_thread,
                NULL, NULL, NULL, IMU_PRIO, 0, 0);

/* ========================= 对外 API ========================= */

int imu_init(void)
{
    if (!EN_IMU) {
        return 0;
    }

    k_sem_init(&imu_start_sem, 0, 1);
    k_mutex_init(&fifo_lock);

    fifo_head = 0;
    fifo_tail = 0;
    seq_imu   = 0;

    if (!device_is_ready(imu_i2c)) {
        LOGF("IMU I2C device not ready in imu_init()\n");
        return -ENODEV;
    }

    /* 上电时配置 IMU 为 200Hz 输出（RRATE=0x0B） */
    (void)imu_config_200hz();

    LOGF("IMU init OK (addr=0x%02X)\n", IMU_I2C_ADDR);
    return 0;
}

void imu_start(void)
{
    if (!EN_IMU) return;
    (void)k_sem_give(&imu_start_sem);
}

/* BLE 端通过 'R' 帧调用：设置 “发送 fps” 和 “phase_ms” 时隙
 *
 *  - target_fps: 本节点希望的发包频率（例如 200/100/50/120 等）
 *  - phase_ms  : 相位偏移（用于多 TX 错开发包）
 *
 *  具体行为：
 *    - IMU 始终以 IMU_ODR_HZ 采样（例如 200Hz）
 *    - 发送线程以 target_fps 周期从 FIFO 取样本，并聚合：
 *
 *        ideal_samples = clamp(IMU_ODR_HZ / target_fps, 1, IMU_SAMPLES_PER_FRAME_MAX)
 *
 *      然后打成一帧 'I' 包发出。
 *
 *  典型配置：
 *    - 单 TX：RSLOT slot 200 0   → 200Hz 发包，每帧 1 sample
 *    - 10×TX：RSLOT slot 50  phase → 50Hz 发包，每帧最多 4 sample（等效 200Hz）
 *    - 你想要的：RSLOT slot 120 phase → 120Hz 发包，每帧约 1~2 sample
 */
void imu_set_rate_phase(uint16_t target_fps, uint16_t phase_ms)
{
    if (target_fps == 0) {
        target_fps = IMU_FPS_DEFAULT;
    }

    if (target_fps > IMU_ODR_HZ) {
        target_fps = IMU_ODR_HZ;  /* 给个合理上限：不超过 IMU ODR */
    }

    g_target_fps = target_fps;
    g_phase_ms   = phase_ms;

    LOGF("IMU rate cfg: send_fps=%u, phase=%u ms\n",
         (unsigned int)g_target_fps, (unsigned int)g_phase_ms);
}
```
